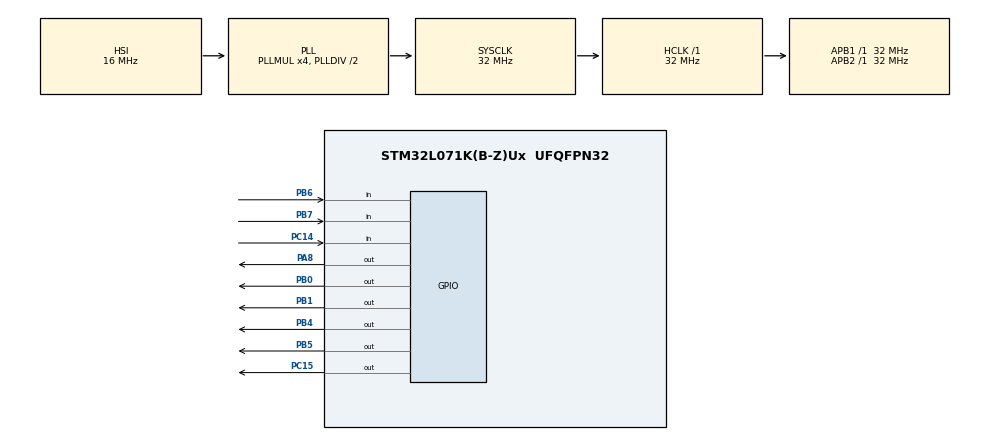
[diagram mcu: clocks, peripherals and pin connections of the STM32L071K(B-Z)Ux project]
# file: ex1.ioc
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Mcu.Family=STM32L0
Mcu.Name=STM32L071K(B-Z)Ux
Mcu.Package=UFQFPN32
PA13.Mode=Serial_Wire
PA13.Signal=SYS_SWDIO
PA14.Mode=Serial_Wire
PA14.Signal=SYS_SWCLK
PA8.Signal=GPIO_Output
PB0.Signal=GPIO_Output
PB1.Signal=GPIO_Output
PB4.Signal=GPIO_Output
PB5.Signal=GPIO_Output
PB6.Signal=GPIO_Input
PB7.Signal=GPIO_Input
PC14-OSC32_IN.Signal=GPIO_Input
PC15-OSC32_OUT.Signal=GPIO_Output
ProjectManager.HeapSize=0x200
ProjectManager.StackSize=0x400
ProjectManager.TargetToolchain=MDK-ARM V5
RCC.AHBFreq_Value=32000000
RCC.APB1Freq_Value=32000000
RCC.APB1TimFreq_Value=32000000
RCC.APB2Freq_Value=32000000
RCC.APB2TimFreq_Value=32000000
RCC.HCLKFreq_Value=32000000
RCC.HSI16_VALUE=16000000
RCC.HSI_VALUE=16000000
RCC.LSE_VALUE=32768
RCC.MSI_VALUE=2097000
RCC.PLLMUL=RCC_PLLMUL_4
RCC.SYSCLKFreq_VALUE=32000000
RCC.SYSCLKSource=RCC_SYSCLKSOURCE_PLLCLK
RCC.VCOOutputFreq_Value=64000000
board=custom

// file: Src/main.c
/* USER CODE BEGIN Header */
/**
  ******************************************************************************
  * @file           : main.c
  * @brief          : Main program body
  ******************************************************************************
  * @attention
  *
  * <h2><center>&copy; Copyright (c) 2019 STMicroelectronics.
  * All rights reserved.</center></h2>
  *
  * This software component is licensed by ST under BSD 3-Clause license,
  * the "License"; You may not use this file except in compliance with the
  * License. You may obtain a copy of the License at:
  *                        opensource.org/licenses/BSD-3-Clause
  *
  ******************************************************************************
  */
/* USER CODE END Header */

#include "main.h"
#include "gpio.h"
#include "key.h"

void SystemClock_Config(void);

void Task_BrdInit(void)
{
    HAL_GPIO_WritePin(GPIOC, GPIO_PIN_15, GPIO_PIN_SET);

    OLED_PowerControl(ENABLE);

    HAL_Delay(200);
    OLED_Init();
    OLED_Clear();

    OLED_ShowString(0, 0, (unsigned char *)"                ", 16);
    OLED_ShowString(0, 2, (unsigned char *)"                ", 16);

}

int main(void)
{

  /* MCU Configuration--------------------------------------------------------*/

  /* Reset of all peripherals, Initializes the Flash interface and the Systick. */
  HAL_Init();

  /* Configure the system clock */
  SystemClock_Config();

  /* Initialize all configured peripherals */
  MX_GPIO_Init();
  /* USER CODE BEGIN 2 */
	Task_BrdInit();

  /* USER CODE END 2 */

  /* Infinite loop */
  /* USER CODE BEGIN WHILE */

		char lcdLine_1st_line[16];
    char lcdLine_2st_line[16];
		unsigned int a;
//	Keyboard_Init();
  while (1)
  {
    /* USER CODE END WHILE */

    /* USER CODE BEGIN 3 */
			a=key2();
//			if(a==21) HAL_GPIO_TogglePin(GPIOC, GPIO_PIN_15);
//			if(a==23) HAL_GPIO_TogglePin(GPIOC, GPIO_PIN_15);
			if (a != 0)
			{
				sprintf(lcdLine_1st_line,"B:%d",a);
				OLED_ShowString(0, 0, (unsigned char *)lcdLine_1st_line, 16);
				a=0;
			}
			sprintf(lcdLine_2st_line, "Hello World    ");
			OLED_ShowString(0, 2, (unsigned char *)lcdLine_2st_line, 16);
   }
  /* USER CODE END 3 */
}

void SystemClock_Config(void)
{
  RCC_OscInitTypeDef RCC_OscInitStruct = {0};
  RCC_ClkInitTypeDef RCC_ClkInitStruct = {0};

  /** Configure the main internal regulator output voltage
  */
  __HAL_PWR_VOLTAGESCALING_CONFIG(PWR_REGULATOR_VOLTAGE_SCALE1);
  /** Initializes the CPU, AHB and APB busses clocks
  */
  RCC_OscInitStruct.OscillatorType = RCC_OSCILLATORTYPE_HSI;
  RCC_OscInitStruct.HSIState = RCC_HSI_ON;
  RCC_OscInitStruct.HSICalibrationValue = RCC_HSICALIBRATION_DEFAULT;
  RCC_OscInitStruct.PLL.PLLState = RCC_PLL_ON;
  RCC_OscInitStruct.PLL.PLLSource = RCC_PLLSOURCE_HSI;
  RCC_OscInitStruct.PLL.PLLMUL = RCC_PLLMUL_4;
  RCC_OscInitStruct.PLL.PLLDIV = RCC_PLLDIV_2;
  if (HAL_RCC_OscConfig(&RCC_OscInitStruct) != HAL_OK)
  {
    Error_Handler();
  }
  /** Initializes the CPU, AHB and APB busses clocks
  */
  RCC_ClkInitStruct.ClockType = RCC_CLOCKTYPE_HCLK|RCC_CLOCKTYPE_SYSCLK
                              |RCC_CLOCKTYPE_PCLK1|RCC_CLOCKTYPE_PCLK2;
  RCC_ClkInitStruct.SYSCLKSource = RCC_SYSCLKSOURCE_PLLCLK;
  RCC_ClkInitStruct.AHBCLKDivider = RCC_SYSCLK_DIV1;
  RCC_ClkInitStruct.APB1CLKDivider = RCC_HCLK_DIV1;
  RCC_ClkInitStruct.APB2CLKDivider = RCC_HCLK_DIV1;

  if (HAL_RCC_ClockConfig(&RCC_ClkInitStruct, FLASH_LATENCY_1) != HAL_OK)
  {
    Error_Handler();
  }
}

void Error_Handler(void)
{
}

/************************ (C) COPYRIGHT STMicroelectronics *****END OF FILE****/
